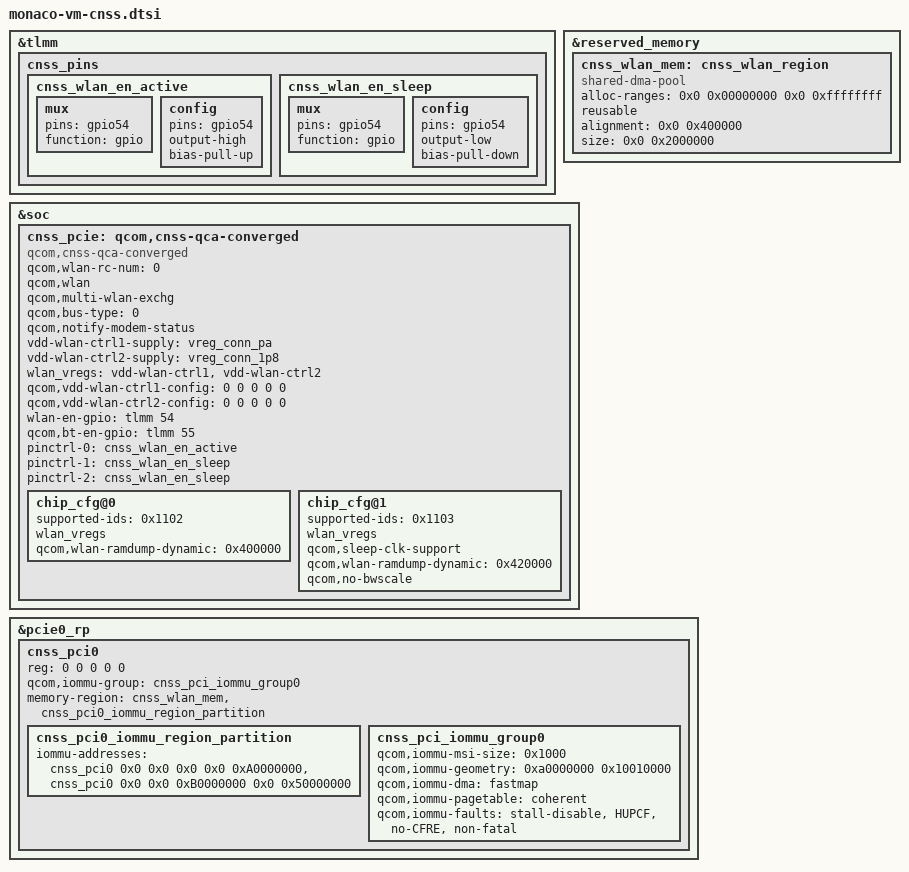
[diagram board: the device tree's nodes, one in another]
// SPDX-License-Identifier: BSD-3-Clause

/*
 * Copyright (c) Qualcomm Technologies, Inc. and/or its subsidiaries.
 */

#include <dt-bindings/interconnect/qcom,monaco_auto.h>

&tlmm {
	cnss_pins: cnss_pins {
		cnss_wlan_en_active: cnss_wlan_en_active {
			mux {
				pins = "gpio54";
				function = "gpio";
			};

			config {
				pins = "gpio54";
				output-high;
				bias-pull-up;
			};
		};

		cnss_wlan_en_sleep: cnss_wlan_en_sleep {
			mux {
				pins = "gpio54";
				function = "gpio";
			};

			config {
				pins = "gpio54";
				output-low;
				bias-pull-down;
			};
		};
	};
};

&reserved_memory {
	cnss_wlan_mem: cnss_wlan_region {
		compatible = "shared-dma-pool";
		alloc-ranges = <0x0 0x00000000 0x0 0xffffffff>;
		reusable;
		alignment = <0x0 0x400000>;
		size = <0x0 0x2000000>;
	};
};

&soc {
	cnss_pcie: qcom,cnss-qca-converged {
		compatible = "qcom,cnss-qca-converged";
		qcom,wlan-rc-num = <0>;
		qcom,wlan;
		qcom,multi-wlan-exchg;
		qcom,bus-type=<0>;
		qcom,notify-modem-status;

		#address-cells=<1>;
		#size-cells=<1>;
		ranges = <0xb0000000 0xb0000000 0x10000>;

		vdd-wlan-ctrl1-supply = <&vreg_conn_pa>;
		vdd-wlan-ctrl2-supply = <&vreg_conn_1p8>;

		wlan_vregs = "vdd-wlan-ctrl1", "vdd-wlan-ctrl2";
		qcom,vdd-wlan-ctrl1-config = <0 0 0 0 0>;
		qcom,vdd-wlan-ctrl2-config = <0 0 0 0 0>;
		/* no vote-off as sw_ctrl is not supported */
		wlan-en-gpio = <&tlmm 54 0>;
		qcom,bt-en-gpio = <&tlmm 55 0>;
		pinctrl-names = "wlan_en_active", "wlan_en_sleep", "default";
		pinctrl-0 = <&cnss_wlan_en_active>;
		pinctrl-1 = <&cnss_wlan_en_sleep>;
		pinctrl-2 = <&cnss_wlan_en_sleep>;

		chip_cfg@0 {
			supported-ids = <0x1102>;
			wlan_vregs;
			qcom,wlan-ramdump-dynamic = <0x400000>;
		};

		chip_cfg@1 {
			supported-ids = <0x1103>;
			wlan_vregs;
			qcom,sleep-clk-support;
			qcom,wlan-ramdump-dynamic = <0x420000>;
			qcom,no-bwscale;
		};

	};
};

&pcie0_rp {
	cnss_pci0: cnss_pci0 {
		reg = <0 0 0 0 0>;
		qcom,iommu-group = <&cnss_pci_iommu_group0>;
		memory-region = <&cnss_wlan_mem &cnss_pci0_iommu_region_partition>;

		#address-cells = <1>;
		#size-cells = <1>;

		cnss_pci0_iommu_region_partition: cnss_pci0_iommu_region_partition {
			iommu-addresses = <&cnss_pci0 0x0 0x0 0x0 0x0 0xA0000000>,
					  <&cnss_pci0 0x0 0x0 0xB0000000 0x0 0x50000000>;
		};

		cnss_pci_iommu_group0: cnss_pci_iommu_group0 {
			qcom,iommu-msi-size = <0x1000>;
			qcom,iommu-geometry = <0xa0000000 0x10010000>;
			qcom,iommu-dma = "fastmap";
			qcom,iommu-pagetable = "coherent";
			qcom,iommu-faults = "stall-disable", "HUPCF", "no-CFRE",
					    "non-fatal";
		};
	};
};
